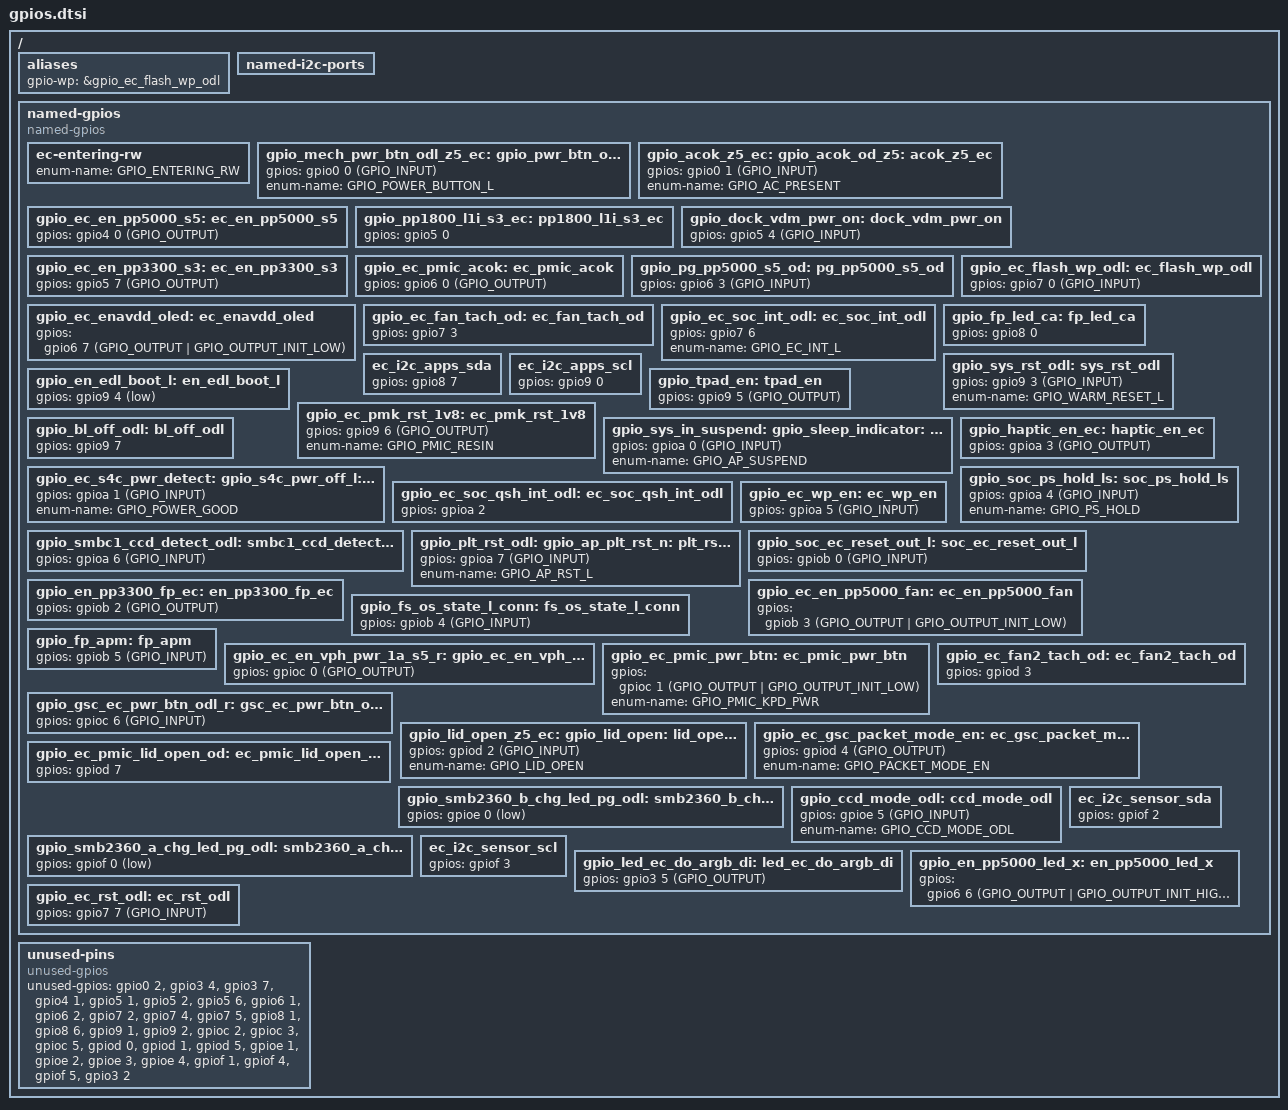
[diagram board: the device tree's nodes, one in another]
/* Copyright 2025 The ChromiumOS Authors
 * Use of this source code is governed by a BSD-style license that can be
 * found in the LICENSE file.
 */

/ {
	aliases {
		gpio-wp = &gpio_ec_flash_wp_odl;
	};

	/*
	 * The I2C port is being removed to free up its
	 * pins for use as GPIOs.
	 */
	named-i2c-ports {
		/delete-node/ ec_i2c_tp;
	};

	named-gpios {
		compatible = "named-gpios";

		/* The legacy system code requires GPIO_ENTERING_RW symbol. */
		ec-entering-rw {
			enum-name = "GPIO_ENTERING_RW";
		};
		gpio_mech_pwr_btn_odl_z5_ec: mech_pwr_btn_odl_z5_ec {
			gpios = <&gpio0 0 (GPIO_INPUT)>;
			enum-name = "GPIO_POWER_BUTTON_L";
		};
		gpio_acok_z5_ec: acok_z5_ec {
			gpios = <&gpio0 1 (GPIO_INPUT)>;
			enum-name = "GPIO_AC_PRESENT";
		};
		gpio_ec_en_pp5000_s5: ec_en_pp5000_s5 {
			gpios = <&gpio4 0 (GPIO_OUTPUT)>;
		};
		gpio_pp1800_l1i_s3_ec: pp1800_l1i_s3_ec {
			gpios = <&gpio5 0 (GPIO_INPUT | GPIO_VOLTAGE_1P8)>;
		};
		gpio_dock_vdm_pwr_on: dock_vdm_pwr_on {
			gpios = <&gpio5 4 (GPIO_INPUT)>;
		};
		gpio_ec_en_pp3300_s3: ec_en_pp3300_s3 {
			gpios = <&gpio5 7 (GPIO_OUTPUT)>;
		};
		gpio_ec_pmic_acok: ec_pmic_acok {
			gpios = <&gpio6 0 (GPIO_OUTPUT)>;
		};
		gpio_pg_pp5000_s5_od: pg_pp5000_s5_od {
			gpios = <&gpio6 3 (GPIO_INPUT)>;
		};
		gpio_ec_enavdd_oled: ec_enavdd_oled {
			gpios = <&gpio6 7 (GPIO_OUTPUT | GPIO_OUTPUT_INIT_LOW)>;
		};
		gpio_ec_flash_wp_odl: ec_flash_wp_odl {
			gpios = <&gpio7 0 (GPIO_INPUT)>;
		};
		gpio_ec_fan_tach_od: ec_fan_tach_od {
			gpios = <&gpio7 3 (GPIO_INPUT | GPIO_PULL_UP)>;
		};
		gpio_ec_soc_int_odl: ec_soc_int_odl {
			gpios = <&gpio7 6 (GPIO_OUTPUT | GPIO_OPEN_DRAIN)>;
			enum-name = "GPIO_EC_INT_L";
		};
		gpio_fp_led_ca: fp_led_ca {
			gpios = <&gpio8 0 (GPIO_OUTPUT | GPIO_OPEN_DRAIN)>;
		};
		ec_i2c_apps_sda {
			gpios = <&gpio8 7 (GPIO_INPUT | GPIO_VOLTAGE_1P8)>;
		};
		ec_i2c_apps_scl {
			gpios = <&gpio9 0 (GPIO_INPUT | GPIO_VOLTAGE_1P8)>;
		};
		gpio_sys_rst_odl: sys_rst_odl {
			gpios = <&gpio9 3 (GPIO_INPUT)>;
			enum-name = "GPIO_WARM_RESET_L";
		};
		gpio_en_edl_boot_l: en_edl_boot_l {
			gpios = <&gpio9 4 (GPIO_OUTPUT | GPIO_OPEN_DRAIN | GPIO_ACTIVE_LOW | GPIO_OUTPUT_INACTIVE)>;
		};
		gpio_tpad_en: tpad_en {
			gpios = <&gpio9 5 (GPIO_OUTPUT)>;
		};
		gpio_ec_pmk_rst_1v8: ec_pmk_rst_1v8 {
			gpios = <&gpio9 6 (GPIO_OUTPUT)>;
			enum-name = "GPIO_PMIC_RESIN";
		};
		gpio_bl_off_odl: bl_off_odl {
			gpios = <&gpio9 7 (GPIO_OUTPUT | GPIO_OUTPUT_INIT_LOW | GPIO_OPEN_DRAIN )>;
		};
		gpio_sys_in_suspend: sys_in_suspend {
			gpios = <&gpioa 0 (GPIO_INPUT)>;
			enum-name = "GPIO_AP_SUSPEND";
		};
		gpio_ec_s4c_pwr_detect: ec_s4c_pwr_detect {
			gpios = <&gpioa 1 (GPIO_INPUT)>;
			enum-name = "GPIO_POWER_GOOD";
		};
		gpio_ec_soc_qsh_int_odl: ec_soc_qsh_int_odl {
			gpios = <&gpioa 2 (GPIO_OUTPUT | GPIO_OPEN_DRAIN)>;
		};
		gpio_haptic_en_ec: haptic_en_ec {
			gpios = <&gpioa 3 (GPIO_OUTPUT)>;
		};
		gpio_soc_ps_hold_ls: soc_ps_hold_ls {
			gpios = <&gpioa 4 (GPIO_INPUT)>;
			enum-name = "GPIO_PS_HOLD";
		};
		gpio_ec_wp_en: ec_wp_en {
			gpios = <&gpioa 5 (GPIO_INPUT)>;
		};
		gpio_smbc1_ccd_detect_odl: smbc1_ccd_detect_odl {
			gpios = <&gpioa 6 (GPIO_INPUT)>;
		};
		gpio_plt_rst_odl: plt_rst_odl {
			gpios = <&gpioa 7 (GPIO_INPUT)>;
			enum-name = "GPIO_AP_RST_L";
		};
		gpio_soc_ec_reset_out_l: soc_ec_reset_out_l {
			gpios = <&gpiob 0 (GPIO_INPUT)>;
		};
		gpio_en_pp3300_fp_ec: en_pp3300_fp_ec {
			gpios = <&gpiob 2 (GPIO_OUTPUT)>;
		};
		gpio_ec_en_pp5000_fan: ec_en_pp5000_fan {
			gpios = <&gpiob 3 (GPIO_OUTPUT | GPIO_OUTPUT_INIT_LOW)>;
		};
		gpio_fs_os_state_l_conn: fs_os_state_l_conn {
			gpios = <&gpiob 4 (GPIO_INPUT)>;
		};
		gpio_fp_apm: fp_apm {
			gpios = <&gpiob 5 (GPIO_INPUT)>;
		};
		gpio_ec_en_vph_pwr_1a_s5_r: ec_en_vph_pwr_1a_s5_r {
			gpios = <&gpioc 0 (GPIO_OUTPUT)>;
		};
		gpio_ec_pmic_pwr_btn: ec_pmic_pwr_btn {
			gpios = <&gpioc 1 (GPIO_OUTPUT | GPIO_OUTPUT_INIT_LOW)>;
			enum-name = "GPIO_PMIC_KPD_PWR";
		};
		gpio_gsc_ec_pwr_btn_odl_r: gsc_ec_pwr_btn_odl_r {
			gpios = <&gpioc 6 (GPIO_INPUT)>;
		};
		gpio_lid_open_z5_ec: lid_open_z5_ec {
			gpios = <&gpiod 2 (GPIO_INPUT)>;
			enum-name = "GPIO_LID_OPEN";
		};
		gpio_ec_fan2_tach_od: ec_fan2_tach_od {
			gpios = <&gpiod 3 (GPIO_INPUT | GPIO_PULL_UP)>;
		};
		gpio_ec_gsc_packet_mode_en: ec_gsc_packet_mode_en {
			gpios = <&gpiod 4 (GPIO_OUTPUT)>;
			enum-name = "GPIO_PACKET_MODE_EN";
		};
		gpio_ec_pmic_lid_open_od: ec_pmic_lid_open_od {
			gpios = <&gpiod 7 (GPIO_OUTPUT | GPIO_OPEN_DRAIN)>;
		};
		gpio_smb2360_b_chg_led_pg_odl: smb2360_b_chg_led_pg_odl {
			gpios = <&gpioe 0 (GPIO_INPUT | GPIO_ACTIVE_LOW)>;
		};
		gpio_ccd_mode_odl: ccd_mode_odl {
			gpios = <&gpioe 5 (GPIO_INPUT)>;
			enum-name = "GPIO_CCD_MODE_ODL";
		};
		gpio_smb2360_a_chg_led_pg_odl: smb2360_a_chg_led_pg_odl {
			gpios = <&gpiof 0 (GPIO_INPUT | GPIO_ACTIVE_LOW)>;
		};
		ec_i2c_sensor_sda {
			gpios = <&gpiof 2 (GPIO_INPUT | GPIO_VOLTAGE_1P8)>;
		};
		ec_i2c_sensor_scl {
			gpios = <&gpiof 3 (GPIO_INPUT | GPIO_VOLTAGE_1P8)>;
		};
		gpio_led_ec_do_argb_di: led_ec_do_argb_di {
			gpios = <&gpio3 5 (GPIO_OUTPUT)>;
		};
		gpio_en_pp5000_led_x: en_pp5000_led_x {
			gpios = <&gpio6 6 (GPIO_OUTPUT | GPIO_OUTPUT_INIT_HIGH)>;
		};
		gpio_ec_rst_odl: ec_rst_odl {
			gpios = <&gpio7 7 (GPIO_INPUT)>;
		};
	};
	unused-pins {
		compatible = "unused-gpios";

		unused-gpios =
			<&gpio0 2 0>,
			<&gpio3 4 0>,
			<&gpio3 7 0>,
			<&gpio4 1 0>,
			<&gpio5 1 0>,
			<&gpio5 2 0>,
			<&gpio5 6 0>,
			<&gpio6 1 0>,
			<&gpio6 2 0>,
			<&gpio7 2 0>,
			<&gpio7 4 0>,
			<&gpio7 5 0>,
			<&gpio8 1 0>,
			<&gpio8 6 0>,
			<&gpio9 1 0>,
			<&gpio9 2 0>,
			<&gpioc 2 0>,
			<&gpioc 3 0>,
			<&gpioc 5 0>,
			<&gpiod 0 0>,
			<&gpiod 1 0>,
			<&gpiod 5 0>,
			<&gpioe 1 0>,
			<&gpioe 2 0>,
			<&gpioe 3 0>,
			<&gpioe 4 0>,
			<&gpiof 1 0>,
			<&gpiof 4 0>,
			<&gpiof 5 0>,
			<&gpio3 2 0>;
	};
};

/*
 * Aliases interrupt to common names
 */
gpio_acok_od_z5: &gpio_acok_z5_ec {};
gpio_lid_open: &gpio_lid_open_z5_ec {};
gpio_pwr_btn_odl: &gpio_mech_pwr_btn_odl_z5_ec {};
gpio_s4c_pwr_off_l: &gpio_ec_s4c_pwr_detect {};
gpio_ap_plt_rst_n: &gpio_plt_rst_odl {};
gpio_sleep_indicator: &gpio_sys_in_suspend {};
gpio_soc_ps_hold_ls: &gpio_soc_ps_hold_ls {};
gpio_sys_rst_odl: &gpio_sys_rst_odl {};

/*
 * Aliases switchcap to common names
 */
gpio_ec_en_vph_pwr_1a: &gpio_ec_en_vph_pwr_1a_s5_r {};
